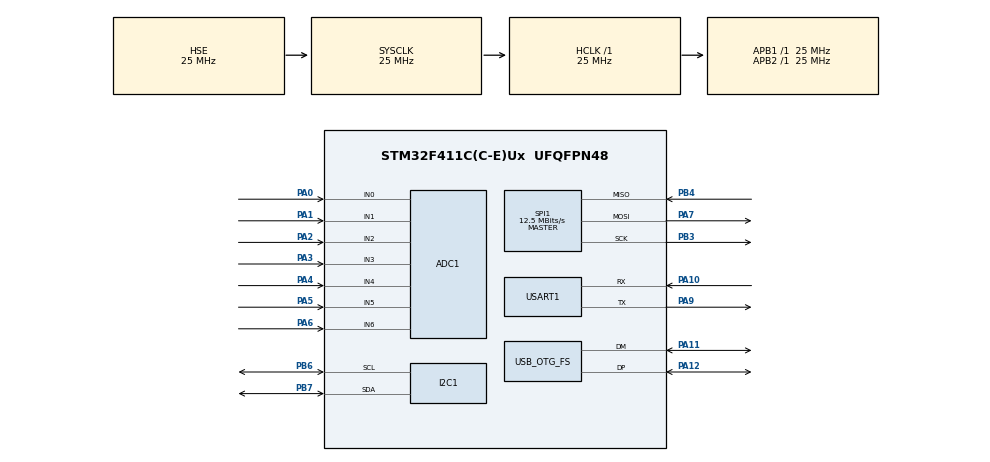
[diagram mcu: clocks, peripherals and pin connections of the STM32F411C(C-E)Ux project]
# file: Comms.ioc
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ADC1.Channel-0\#ChannelRegularConversion=ADC_CHANNEL_0
ADC1.NbrOfConversionFlag=1
ADC1.Rank-0\#ChannelRegularConversion=1
ADC1.SamplingTime-0\#ChannelRegularConversion=ADC_SAMPLETIME_3CYCLES
ADC1.master=1
IWDG.Prescaler=IWDG_PRESCALER_256
Mcu.Family=STM32F4
Mcu.Name=STM32F411C(C-E)Ux
Mcu.Package=UFQFPN48
NVIC.PriorityGroup=NVIC_PRIORITYGROUP_4
PA0-WKUP.Signal=ADCx_IN0
PA1.Signal=ADCx_IN1
PA10.Mode=Asynchronous
PA10.Signal=USART1_RX
PA11.Mode=Host_Only
PA11.Signal=USB_OTG_FS_DM
PA12.Mode=Host_Only
PA12.Signal=USB_OTG_FS_DP
PA13.Mode=Serial_Wire
PA13.Signal=SYS_JTMS-SWDIO
PA14.Mode=Serial_Wire
PA14.Signal=SYS_JTCK-SWCLK
PA2.Signal=ADCx_IN2
PA3.Signal=ADCx_IN3
PA4.Signal=ADCx_IN4
PA5.Signal=ADCx_IN5
PA6.Signal=ADCx_IN6
PA7.Mode=Full_Duplex_Master
PA7.Signal=SPI1_MOSI
PA9.Mode=Asynchronous
PA9.Signal=USART1_TX
PB3.Mode=Full_Duplex_Master
PB3.Signal=SPI1_SCK
PB4.Mode=Full_Duplex_Master
PB4.Signal=SPI1_MISO
PB6.GPIO_Pu=GPIO_PULLUP
PB6.Mode=I2C
PB6.Signal=I2C1_SCL
PB7.GPIO_Pu=GPIO_PULLUP
PB7.Mode=I2C
PB7.Signal=I2C1_SDA
PH0\ -\ OSC_IN.Mode=HSE-External-Oscillator
PH0\ -\ OSC_IN.Signal=RCC_OSC_IN
PH1\ -\ OSC_OUT.Mode=HSE-External-Oscillator
PH1\ -\ OSC_OUT.Signal=RCC_OSC_OUT
ProjectManager.HeapSize=0x200
ProjectManager.StackSize=0x400
ProjectManager.TargetToolchain=STM32CubeIDE
RCC.48MHZClocksFreq_Value=48000000
RCC.AHBFreq_Value=25000000
RCC.APB1Freq_Value=25000000
RCC.APB1TimFreq_Value=25000000
RCC.APB2Freq_Value=25000000
RCC.APB2TimFreq_Value=25000000
RCC.CortexFreq_Value=25000000
RCC.HCLKFreq_Value=25000000
RCC.HSE_VALUE=25000000
RCC.HSI_VALUE=16000000
RCC.LSE_VALUE=32768
RCC.PLLM=15
RCC.PLLN=144
RCC.PLLQ=5
RCC.SYSCLKFreq_VALUE=25000000
RCC.SYSCLKSource=RCC_SYSCLKSOURCE_HSE
RCC.VCOOutputFreq_Value=240000000
SH.ADCx_IN0.0=ADC1_IN0,IN0
SH.ADCx_IN1.0=ADC1_IN1,IN1
SH.ADCx_IN2.0=ADC1_IN2,IN2
SH.ADCx_IN3.0=ADC1_IN3,IN3
SH.ADCx_IN4.0=ADC1_IN4,IN4
SH.ADCx_IN5.0=ADC1_IN5,IN5
SH.ADCx_IN6.0=ADC1_IN6,IN6
SPI1.CalculateBaudRate=12.5 MBits/s
SPI1.Direction=SPI_DIRECTION_2LINES
SPI1.Mode=SPI_MODE_MASTER
SPI1.VirtualType=VM_MASTER
USART1.VirtualMode=VM_ASYNC
USB_OTG_FS.VirtualMode=Host_Only
USB_OTG_FS.phy_itface=HCD_PHY_EMBEDDED
VP_IWDG_VS_IWDG.Mode=IWDG_Activate
VP_TIM5_VS_ClockSourceITR.Mode=TriggerSource_ITR0
board=custom

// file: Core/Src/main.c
/* USER CODE BEGIN Header */
/**
  ******************************************************************************
  * @file           : main.c
  * @brief          : Main program body
  ******************************************************************************
  * @attention
  *
  * <h2><center>&copy; Copyright (c) 2021 STMicroelectronics.
  * All rights reserved.</center></h2>
  *
  * This software component is licensed by ST under BSD 3-Clause license,
  * the "License"; You may not use this file except in compliance with the
  * License. You may obtain a copy of the License at:
  *                        opensource.org/licenses/BSD-3-Clause
  *
  ******************************************************************************
  */
/* USER CODE END Header */
/* Includes ---------------------------------------------------------------- */
#include "main.h"
#include <string.h>
#include <math.h>
#include <stdbool.h>
#include "sx126x.h"
#include "radio.h"
#include "sx126x-hal.h"

/* USER CODE BEGIN PD */
#define RF_FREQUENCY 868000000             // 868 MHz
#define TX_OUTPUT_POWER 22                 // 22 dBm
#define LORA_SPREADING_FACTOR 9            // [0x09 --> SF9]
#define LORA_BANDWIDTH 4                   // [0x04 --> 125 kHz]
#define LORA_CODING_RATE 1                 // [0x01 --> CR=4/5]
#define LORA_LOW_DATA_RATE_OPTIMIZE 0      // [0x00 --> LowDataRateOptimize OFF]
#define PREAMBLE LENGTH 8                  // CSS modulations usually have 8 preamble symbols
#define HEADER_TYPE 0                      // [0 --> Explicit header]
#define PAYLOAD_LENGTH 38                  // [38 bytes of payload information]
#define CRC_TYPE 0                         // [0 --> CRC OFF]
#define INVERT_IQ 0                        // [0 --> Standard IQ setup]
// Check CAD
// BufferBaseAddress
// LoRaSymbNumTimeout
#define TX_TIMEOUT_VALUE 13900             // In ms, maximum total time to send 40 packets and receive the ACK
#define BUFFER_SIZE 59                     //Payload size, in bytes.
/* USER CODE END PD */

ADC_HandleTypeDef hadc1;

I2C_HandleTypeDef hi2c1;

IWDG_HandleTypeDef hiwdg;

SPI_HandleTypeDef hspi1;

TIM_HandleTypeDef htim5;

UART_HandleTypeDef huart1;

HCD_HandleTypeDef hhcd_USB_OTG_FS;

uint16_t BufferSize = BUFFER_SIZE;
bool PacketReceived = false;
bool RxTimeoutTimerIrqFlag = false;
uint16_t RxCorrectCnt = 0;
uint16_t RxErrorCnt = 0;
uint16_t RxTimeoutCnt = 0;
uint16_t TxTimeoutCnt = 0;

void SystemClock_Config(void);
static void MX_GPIO_Init(void);
static void MX_ADC1_Init(void);
static void MX_I2C1_Init(void);
static void MX_SPI1_Init(void);
static void MX_USART1_UART_Init(void);
static void MX_USB_OTG_FS_HCD_Init(void);
static void MX_IWDG_Init(void);
static void MX_TIM5_Init(void);

int main(void)
{

  /* MCU Configuration--------------------------------------------------------*/

  /* Reset of all peripherals, Initializes the Flash interface and the Systick. */
  HAL_Init();

  /* Configure the system clock */
  SystemClock_Config();

  /* Initialize all configured peripherals */
  MX_GPIO_Init();
  MX_ADC1_Init();
  MX_I2C1_Init();
  MX_SPI1_Init();
  MX_USART1_UART_Init();
  MX_USB_OTG_FS_HCD_Init();
  MX_IWDG_Init();
  MX_TIM5_Init();

  /* Infinite loop */
  while (1)
  {
	  configuration();
  }
}

void SystemClock_Config(void)
{
  RCC_OscInitTypeDef RCC_OscInitStruct = {0};
  RCC_ClkInitTypeDef RCC_ClkInitStruct = {0};

  /** Configure the main internal regulator output voltage
  */
  __HAL_RCC_PWR_CLK_ENABLE();
  __HAL_PWR_VOLTAGESCALING_CONFIG(PWR_REGULATOR_VOLTAGE_SCALE1);
  /** Initializes the RCC Oscillators according to the specified parameters
  * in the RCC_OscInitTypeDef structure.
  */
  RCC_OscInitStruct.OscillatorType = RCC_OSCILLATORTYPE_LSI|RCC_OSCILLATORTYPE_HSE;
  RCC_OscInitStruct.HSEState = RCC_HSE_ON;
  RCC_OscInitStruct.LSIState = RCC_LSI_ON;
  RCC_OscInitStruct.PLL.PLLState = RCC_PLL_ON;
  RCC_OscInitStruct.PLL.PLLSource = RCC_PLLSOURCE_HSE;
  RCC_OscInitStruct.PLL.PLLM = 15;
  RCC_OscInitStruct.PLL.PLLN = 144;
  RCC_OscInitStruct.PLL.PLLP = RCC_PLLP_DIV2;
  RCC_OscInitStruct.PLL.PLLQ = 5;
  if (HAL_RCC_OscConfig(&RCC_OscInitStruct) != HAL_OK)
  {
    Error_Handler();
  }
  /** Initializes the CPU, AHB and APB buses clocks
  */
  RCC_ClkInitStruct.ClockType = RCC_CLOCKTYPE_HCLK|RCC_CLOCKTYPE_SYSCLK
                              |RCC_CLOCKTYPE_PCLK1|RCC_CLOCKTYPE_PCLK2;
  RCC_ClkInitStruct.SYSCLKSource = RCC_SYSCLKSOURCE_HSE;
  RCC_ClkInitStruct.AHBCLKDivider = RCC_SYSCLK_DIV1;
  RCC_ClkInitStruct.APB1CLKDivider = RCC_HCLK_DIV1;
  RCC_ClkInitStruct.APB2CLKDivider = RCC_HCLK_DIV1;

  if (HAL_RCC_ClockConfig(&RCC_ClkInitStruct, FLASH_LATENCY_0) != HAL_OK)
  {
    Error_Handler();
  }
}

static void MX_ADC1_Init(void)
{

  ADC_ChannelConfTypeDef sConfig = {0};

  /** Configure the global features of the ADC (Clock, Resolution, Data Alignment and number of conversion)
  */
  hadc1.Instance = ADC1;
  hadc1.Init.ClockPrescaler = ADC_CLOCK_SYNC_PCLK_DIV2;
  hadc1.Init.Resolution = ADC_RESOLUTION_12B;
  hadc1.Init.ScanConvMode = DISABLE;
  hadc1.Init.ContinuousConvMode = DISABLE;
  hadc1.Init.DiscontinuousConvMode = DISABLE;
  hadc1.Init.ExternalTrigConvEdge = ADC_EXTERNALTRIGCONVEDGE_NONE;
  hadc1.Init.ExternalTrigConv = ADC_SOFTWARE_START;
  hadc1.Init.DataAlign = ADC_DATAALIGN_RIGHT;
  hadc1.Init.NbrOfConversion = 1;
  hadc1.Init.DMAContinuousRequests = DISABLE;
  hadc1.Init.EOCSelection = ADC_EOC_SINGLE_CONV;
  if (HAL_ADC_Init(&hadc1) != HAL_OK)
  {
    Error_Handler();
  }
  /** Configure for the selected ADC regular channel its corresponding rank in the sequencer and its sample time.
  */
  sConfig.Channel = ADC_CHANNEL_0;
  sConfig.Rank = 1;
  sConfig.SamplingTime = ADC_SAMPLETIME_3CYCLES;
  if (HAL_ADC_ConfigChannel(&hadc1, &sConfig) != HAL_OK)
  {
    Error_Handler();
  }

}

static void MX_I2C1_Init(void)
{

  hi2c1.Instance = I2C1;
  hi2c1.Init.ClockSpeed = 100000;
  hi2c1.Init.DutyCycle = I2C_DUTYCYCLE_2;
  hi2c1.Init.OwnAddress1 = 0;
  hi2c1.Init.AddressingMode = I2C_ADDRESSINGMODE_7BIT;
  hi2c1.Init.DualAddressMode = I2C_DUALADDRESS_DISABLE;
  hi2c1.Init.OwnAddress2 = 0;
  hi2c1.Init.GeneralCallMode = I2C_GENERALCALL_DISABLE;
  hi2c1.Init.NoStretchMode = I2C_NOSTRETCH_DISABLE;
  if (HAL_I2C_Init(&hi2c1) != HAL_OK)
  {
    Error_Handler();
  }

}

static void MX_IWDG_Init(void)
{

  hiwdg.Instance = IWDG;
  hiwdg.Init.Prescaler = IWDG_PRESCALER_256;
  hiwdg.Init.Reload = 4095;
  if (HAL_IWDG_Init(&hiwdg) != HAL_OK)
  {
    Error_Handler();
  }

}

static void MX_SPI1_Init(void)
{

  /* SPI1 parameter configuration*/
  hspi1.Instance = SPI1;
  hspi1.Init.Mode = SPI_MODE_MASTER;
  hspi1.Init.Direction = SPI_DIRECTION_2LINES;
  hspi1.Init.DataSize = SPI_DATASIZE_8BIT;
  hspi1.Init.CLKPolarity = SPI_POLARITY_LOW;
  hspi1.Init.CLKPhase = SPI_PHASE_1EDGE;
  hspi1.Init.NSS = SPI_NSS_SOFT;
  hspi1.Init.BaudRatePrescaler = SPI_BAUDRATEPRESCALER_2;
  hspi1.Init.FirstBit = SPI_FIRSTBIT_MSB;
  hspi1.Init.TIMode = SPI_TIMODE_DISABLE;
  hspi1.Init.CRCCalculation = SPI_CRCCALCULATION_DISABLE;
  hspi1.Init.CRCPolynomial = 10;
  if (HAL_SPI_Init(&hspi1) != HAL_OK)
  {
    Error_Handler();
  }

}

static void MX_TIM5_Init(void)
{

  TIM_SlaveConfigTypeDef sSlaveConfig = {0};
  TIM_MasterConfigTypeDef sMasterConfig = {0};

  htim5.Instance = TIM5;
  htim5.Init.Prescaler = 0;
  htim5.Init.CounterMode = TIM_COUNTERMODE_UP;
  htim5.Init.Period = 4294967295;
  htim5.Init.ClockDivision = TIM_CLOCKDIVISION_DIV1;
  htim5.Init.AutoReloadPreload = TIM_AUTORELOAD_PRELOAD_DISABLE;
  if (HAL_TIM_Base_Init(&htim5) != HAL_OK)
  {
    Error_Handler();
  }
  sSlaveConfig.SlaveMode = TIM_SLAVEMODE_DISABLE;
  sSlaveConfig.InputTrigger = TIM_TS_ITR0;
  if (HAL_TIM_SlaveConfigSynchro(&htim5, &sSlaveConfig) != HAL_OK)
  {
    Error_Handler();
  }
  sMasterConfig.MasterOutputTrigger = TIM_TRGO_RESET;
  sMasterConfig.MasterSlaveMode = TIM_MASTERSLAVEMODE_DISABLE;
  if (HAL_TIMEx_MasterConfigSynchronization(&htim5, &sMasterConfig) != HAL_OK)
  {
    Error_Handler();
  }

}

static void MX_USART1_UART_Init(void)
{

  huart1.Instance = USART1;
  huart1.Init.BaudRate = 115200;
  huart1.Init.WordLength = UART_WORDLENGTH_8B;
  huart1.Init.StopBits = UART_STOPBITS_1;
  huart1.Init.Parity = UART_PARITY_NONE;
  huart1.Init.Mode = UART_MODE_TX_RX;
  huart1.Init.HwFlowCtl = UART_HWCONTROL_NONE;
  huart1.Init.OverSampling = UART_OVERSAMPLING_16;
  if (HAL_UART_Init(&huart1) != HAL_OK)
  {
    Error_Handler();
  }

}

static void MX_USB_OTG_FS_HCD_Init(void)
{

  hhcd_USB_OTG_FS.Instance = USB_OTG_FS;
  hhcd_USB_OTG_FS.Init.Host_channels = 8;
  hhcd_USB_OTG_FS.Init.speed = HCD_SPEED_FULL;
  hhcd_USB_OTG_FS.Init.dma_enable = DISABLE;
  hhcd_USB_OTG_FS.Init.phy_itface = HCD_PHY_EMBEDDED;
  hhcd_USB_OTG_FS.Init.Sof_enable = DISABLE;
  if (HAL_HCD_Init(&hhcd_USB_OTG_FS) != HAL_OK)
  {
    Error_Handler();
  }

}

static void MX_GPIO_Init(void)
{

  /* GPIO Ports Clock Enable */
  __HAL_RCC_GPIOH_CLK_ENABLE();
  __HAL_RCC_GPIOA_CLK_ENABLE();
  __HAL_RCC_GPIOB_CLK_ENABLE();

}

void Error_Handler(void)
{
  __disable_irq();
  while (1)
  {
  }
}

/************************ (C) COPYRIGHT STMicroelectronics *****END OF FILE****/
